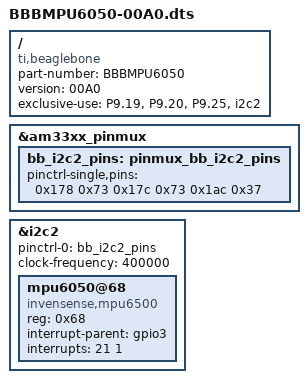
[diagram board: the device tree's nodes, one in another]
/*
 * Custom overlay for MPU6050 for Beaglebone Blue
 * Author: Kiran Kumar Lekkala
 */
/dts-v1/;
/plugin/;

/ {
	compatible = "ti,beaglebone", "ti,beaglebone-black", "ti,beaglebone-green";

	/* identification */
	part-number = "BBBMPU6050";
	version = "00A0";

	/* state the resources this cape uses */
	exclusive-use =
		/* the pin header uses */
		"P9.19",	/* i2c2_sda */
		"P9.20",	/* i2c2_scl */
		"P9.25",	/* imu_interrupt*/
		/* the hardware ip uses */
		"i2c2";

	fragment@0 {
		target = <&am33xx_pinmux>;
		__overlay__ {
			bb_i2c2_pins: pinmux_bb_i2c2_pins {
				pinctrl-single,pins = <
					0x178 0x73	/* i2c2_sda, SLEWCTRL_SLOW | INPUT_PULLUP | MODE3 */
					0x17c 0x73	/* i2c2_scl, SLEWCTRL_SLOW | INPUT_PULLUP | MODE3 */
					0x1ac 0x37	/* i2c2_int, MPU-9150 INTERRUPT IN*/
				>;
			};
		};
	};

	fragment@1 {
		target = <&i2c2>;
		__overlay__ {
			status = "okay";
			pinctrl-names = "default";
			pinctrl-0 = <&bb_i2c2_pins>;

			/* this is the configuration part */
			clock-frequency = <400000>;

			#address-cells = <1>;
			#size-cells = <0>;

			/* add any i2c devices on the bus here */

			mpu6050@68 {
				compatible = "invensense,mpu6500";
				reg = <0x68>;
				interrupt-parent = <&gpio3>;
				interrupts = <21 1>;
	};
		};
	};
};
